# CBASS_INFRA1_QOS register map
Vendor: Texas Instruments
Peripheral module from a debugger description file (folder am243x).
Registers are 32-bit, read-write, reset 0x7000 unless marked. A register's access mark holds for its fields unless they carry their own. Offsets are as the file gives them; lines under a group give offsets from that group; [hi:lo] are bit positions; {n}, {i} and the like mark numbered series; 'fields as' and 'values as' point back to an identical list; <NAME> marks a mode.

## CBASS_INFRA1_QOS
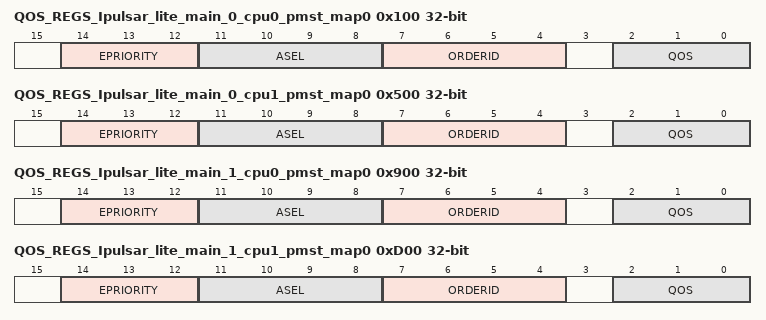
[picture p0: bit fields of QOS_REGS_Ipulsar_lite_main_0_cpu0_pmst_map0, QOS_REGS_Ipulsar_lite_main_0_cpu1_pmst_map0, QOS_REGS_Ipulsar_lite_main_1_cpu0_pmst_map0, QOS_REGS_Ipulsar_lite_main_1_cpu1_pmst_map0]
0x100 QOS_REGS_Ipulsar_lite_main_0_cpu0_pmst_map0 — The Map Register defines the fields for the master Ipulsar_lite_main_0.cpu0_pmst per channel.
  [14:12] EPRIORITY — epriority signal for channel N.
  [11:8] ASEL — asel signal for channel N. 0 = SOC address. 1-15 = peripheral address.
  [7:4] ORDERID — orderid signal for channel N.
  [2:0] QOS — qos signal for channel N.
0x500 QOS_REGS_Ipulsar_lite_main_0_cpu1_pmst_map0 — The Map Register defines the fields for the master Ipulsar_lite_main_0.cpu1_pmst per channel.
  fields as QOS_REGS_Ipulsar_lite_main_0_cpu0_pmst_map0
0x900 QOS_REGS_Ipulsar_lite_main_1_cpu0_pmst_map0 — The Map Register defines the fields for the master Ipulsar_lite_main_1.cpu0_pmst per channel.
  fields as QOS_REGS_Ipulsar_lite_main_0_cpu0_pmst_map0
0xD00 QOS_REGS_Ipulsar_lite_main_1_cpu1_pmst_map0 — The Map Register defines the fields for the master Ipulsar_lite_main_1.cpu1_pmst per channel.
  fields as QOS_REGS_Ipulsar_lite_main_0_cpu0_pmst_map0
